# ATtiny841 register map
Vendor: Atmel; File version: 1.0
CPU: other r0p0, little endian, no MPU, no FPU, 4 interrupt priority bits
Registers are 8-bit, read-write, reset 0x0 unless marked. A register's access mark holds for its fields unless they carry their own. Offsets are from the block's base; [hi:lo] are bit positions.

## TC1 — Timer/Counter, 16-bit
Base 0x0080002E
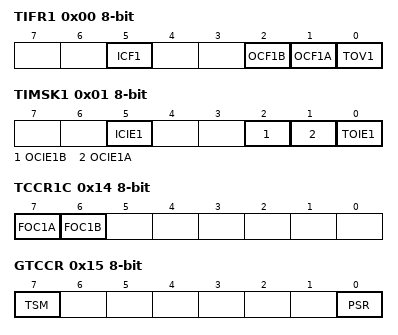
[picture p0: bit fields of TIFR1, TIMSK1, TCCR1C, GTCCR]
0x00 TIFR1 — Timer/Counter Interrupt Flag register (read-only for debugger)
  [5] ICF1 — Timer/Counter1 Input Capture Flag
  [2] OCF1B — Timer/Counter1 Output Compare B Match Flag
  [1] OCF1A — Timer/Counter1 Output Compare A Match Flag
  [0] TOV1 — Timer/Counter1 Overflow Flag
0x01 TIMSK1 — Timer/Counter1 Interrupt Mask Register
  [5] ICIE1 — Timer/Counter1 Input Capture Interrupt Enable
  [2] OCIE1B — Timer/Counter1 Output Compare B Match Interrupt Enable
  [1] OCIE1A — Timer/Counter1 Output Compare A Match Interrupt Enable
  [0] TOIE1 — Timer/Counter1 Overflow Interrupt Enable
0x14 TCCR1C — Timer/Counter1 Control Register C (write-only for debugger)
  [7] FOC1A — Force Output Compare for Channel A
  [6] FOC1B — Force Output Compare for Channel B
0x15 GTCCR — General Timer/Counter Control Register
  [7] TSM — Timer/Counter Synchronization Mode
  [0] PSR — Prescaler Reset Timer/CounterN
0x16 ICR1 16-bit (reset mask 0xFF) — Timer/Counter1 Input Capture Register Bytes
0x1A OCR1B 16-bit (reset mask 0xFF) — Timer/Counter1 Output Compare Register B Bytes
0x1C OCR1A 16-bit (reset mask 0xFF) — Timer/Counter1 Output Compare Register A Bytes
0x1E TCNT1 16-bit (reset mask 0xFF) — Timer/Counter1 Bytes
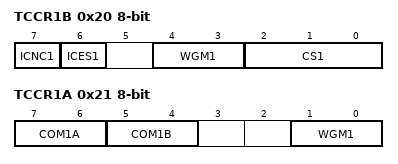
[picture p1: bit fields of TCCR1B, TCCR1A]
0x20 TCCR1B — Timer/Counter1 Control Register B
  [7] ICNC1 — Input Capture 1 Noise Canceler
  [6] ICES1 — Input Capture 1 Edge Select
  [4:3] WGM1 — Waveform Generation Mode Bits
  [2:0] CS1 — Clock Select bits
    0=NO_CLOCK_SOURCE_STOPPED; 1=RUNNING_NO_PRESCALING; 2=RUNNING_CLK_8; 3=RUNNING_CLK_64; 4=RUNNING_CLK_256; 5=RUNNING_CLK_1024; 6=RUNNING_EXTCLK_TN_FALLING_EDGE; 7=RUNNING_EXTCLK_TN_RISING_EDGE
0x21 TCCR1A — Timer/Counter1 Control Register A
  [7:6] COM1A — Compare Output Mode 1A, bits
  [5:4] COM1B — Compare Output Mode 1B, bits
  [1:0] WGM1 — Pulse Width Modulator Select Bits

## TC2 — Timer/Counter, 16-bit
Base 0x00800030
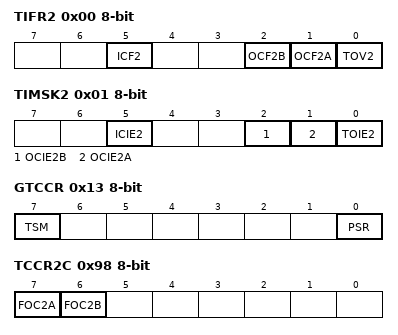
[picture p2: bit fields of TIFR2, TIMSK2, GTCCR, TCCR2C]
0x00 TIFR2 — Timer/Counter Interrupt Flag register (read-only for debugger)
  [5] ICF2 — Timer/Counter2 Input Capture Flag
  [2] OCF2B — Timer/Counter2 Output Compare B Match Flag
  [1] OCF2A — Timer/Counter2 Output Compare A Match Flag
  [0] TOV2 — Timer/Counter2 Overflow Flag
0x01 TIMSK2 — Timer/Counter2 Interrupt Mask Register
  [5] ICIE2 — Timer/Counter2 Input Capture Interrupt Enable
  [2] OCIE2B — Timer/Counter2 Output Compare B Match Interrupt Enable
  [1] OCIE2A — Timer/Counter2 Output Compare A Match Interrupt Enable
  [0] TOIE2 — Timer/Counter2 Overflow Interrupt Enable
0x13 GTCCR — General Timer/Counter Control Register
  [7] TSM — Timer/Counter Synchronization Mode
  [0] PSR — Prescaler Reset Timer/CounterN
0x90 ICR2 16-bit (reset mask 0xFF) — Timer/Counter2 Input Capture Register Bytes
0x92 OCR2B 16-bit (reset mask 0xFF) — Timer/Counter2 Output Compare Register B Bytes
0x94 OCR2A 16-bit (reset mask 0xFF) — Timer/Counter2 Output Compare Register A Bytes
0x96 TCNT2 16-bit (reset mask 0xFF) — Timer/Counter2 Bytes
0x98 TCCR2C — Timer/Counter2 Control Register C (write-only for debugger)
  [7] FOC2A — Force Output Compare for Channel A
  [6] FOC2B — Force Output Compare for Channel B
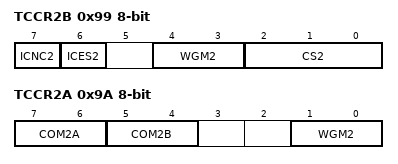
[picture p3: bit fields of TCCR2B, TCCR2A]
0x99 TCCR2B — Timer/Counter2 Control Register B
  [7] ICNC2 — Input Capture 2 Noise Canceler
  [6] ICES2 — Input Capture 2 Edge Select
  [4:3] WGM2 — Waveform Generation Mode Bits
  [2:0] CS2 — Clock Select bits
    0=NO_CLOCK_SOURCE_STOPPED; 1=RUNNING_NO_PRESCALING; 2=RUNNING_CLK_8; 3=RUNNING_CLK_64; 4=RUNNING_CLK_256; 5=RUNNING_CLK_1024; 6=RUNNING_EXTCLK_TN_FALLING_EDGE; 7=RUNNING_EXTCLK_TN_RISING_EDGE
0x9A TCCR2A — Timer/Counter2 Control Register A
  [7:6] COM2A — Compare Output Mode 2A, bits
  [5:4] COM2B — Compare Output Mode 2B, bits
  [1:0] WGM2 — Pulse Width Modulator Select Bits
